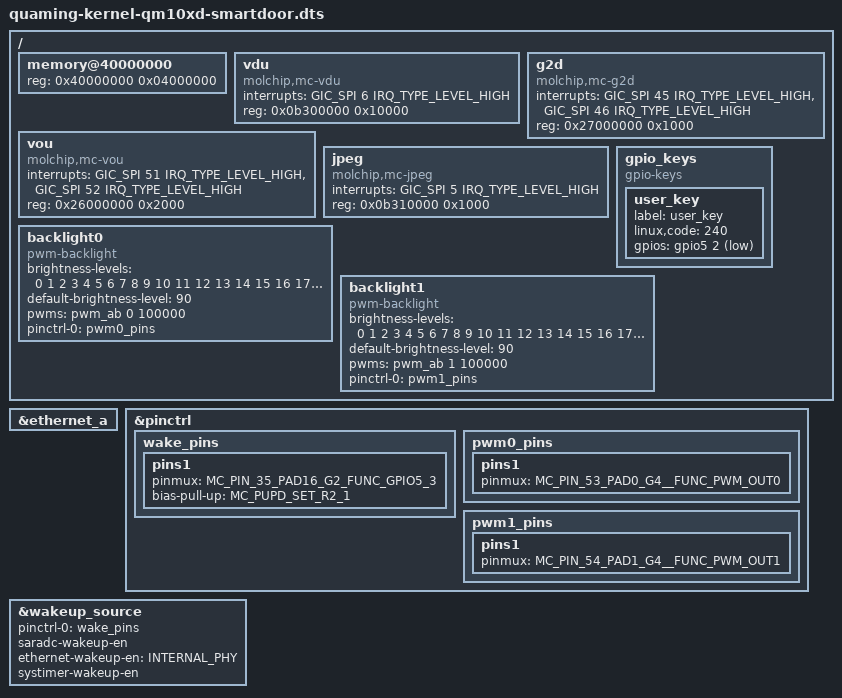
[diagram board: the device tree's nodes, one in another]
/*
 * molchip
 *
 * Cortex-A7
 *
 * HBI-0225B
 */

/dts-v1/;
#include "quaming-kernel-qm10xd-smartdoor.dtsi"
#include "quaming-kernel-qm10xd-smartdoor-pinctrl.dtsi"
#include <dt-bindings/input/input.h>
/ {
	memory@40000000 {
		device_type = "memory";
		reg = <0x40000000 0x04000000>;
	};
	vdu {
		compatible = "molchip,mc-vdu";
		interrupts = <GIC_SPI 6 IRQ_TYPE_LEVEL_HIGH>;
		reg = <0x0b300000 0x10000>;
	};
	g2d {
		compatible = "molchip,mc-g2d";
		interrupts = <GIC_SPI 45 IRQ_TYPE_LEVEL_HIGH>,
					<GIC_SPI 46 IRQ_TYPE_LEVEL_HIGH>;
		reg = <0x27000000 0x1000>;
	};
	vou {
		compatible = "molchip,mc-vou";
		interrupts = <GIC_SPI 51 IRQ_TYPE_LEVEL_HIGH>,
					<GIC_SPI 52 IRQ_TYPE_LEVEL_HIGH>;
		reg = <0x26000000 0x2000>;
	};
	jpeg {
		compatible = "molchip,mc-jpeg";
		interrupts = <GIC_SPI 5 IRQ_TYPE_LEVEL_HIGH>;
		reg = <0x0b310000 0x1000>;
	};

	gpio_keys {
		compatible = "gpio-keys";

		user_key {
			label = "user_key";
			linux,code = <240>; /* 240: KEY_UNKOWN */
			gpios = <&gpio5 2 1>; /* 1: GPIO_ACTIVE_LOW */
		};
	};

	backlight0: backlight0 {
		compatible = "pwm-backlight";
		brightness-levels = < 0  1  2  3  4  5  6  7  8  9
							10  11  12  13  14  15  16  17  18  19
							20  21  22  23  24  25  26  27  28  29
							30  31  32  33  34  35  36  37  38  39
							40  41  42  43  44  45  46  47  48  49
							50  51  52  53  54  55  56  57  58  59
							60  61  62  63  64  65  66  67  68  69
							70  71  72  73  74  75  76  77  78  79
							80  81  82  83  84  85  86  87  88  89
							90  91  92  93  94  95  96  97  98  99
							100 >;
		default-brightness-level = <90>;
		pwms = <&pwm_ab 0 100000>;
		pinctrl-names = "default";
		pinctrl-0 = <&pwm0_pins>;
		status = "okay";
	};

	backlight1: backlight1 {
		compatible = "pwm-backlight";
		brightness-levels = < 0  1  2  3  4  5  6  7  8  9
							10  11  12  13  14  15  16  17  18  19
							20  21  22  23  24  25  26  27  28  29
							30  31  32  33  34  35  36  37  38  39
							40  41  42  43  44  45  46  47  48  49
							50  51  52  53  54  55  56  57  58  59
							60  61  62  63  64  65  66  67  68  69
							70  71  72  73  74  75  76  77  78  79
							80  81  82  83  84  85  86  87  88  89
							90  91  92  93  94  95  96  97  98  99
							100 >;
		default-brightness-level = <90>;
		pwms = <&pwm_ab 1 100000>;
		pinctrl-names = "default";
		pinctrl-0 = <&pwm1_pins>;
		status = "okay";
	};
};

&ethernet_a {

/* For mphy */
	/*
	phy-mode = "rmii";
	snps,en-rmii-inv;
	snps,inv-sel = <0x1F8>,<0>,<0x1>;
	phy-type = <EXTERNAL_PHY>;
	pinctrl-names = "default";
	pinctrl-0 = <&eth_pins_rmii_defaults>;

	status = "okay";

	mdio {
		phy0: phy@0 {
			reg = <0x1>;
		};
	};
	*/

};

&pinctrl{
	wake_pins:wake_pins {
		pins1 {
           		pinmux = <MC_PIN_35_PAD16_G2_FUNC_GPIO5_3>;
                	bias-pull-up = <MC_PUPD_SET_R2_1>;
		};
	};
	pwm0_pins:pwm0_pins {
		pins1 {
			pinmux = <MC_PIN_53_PAD0_G4__FUNC_PWM_OUT0>;
		};
	};

	pwm1_pins:pwm1_pins {
		pins1 {
			pinmux = <MC_PIN_54_PAD1_G4__FUNC_PWM_OUT1>;
		};
	};
};

&wakeup_source {
//	gpio-wakeup-en = <43>;
        pinctrl-names = "default";
        pinctrl-0 = <&wake_pins>;

	saradc-wakeup-en;
	ethernet-wakeup-en = <INTERNAL_PHY>;
	systimer-wakeup-en;
};

